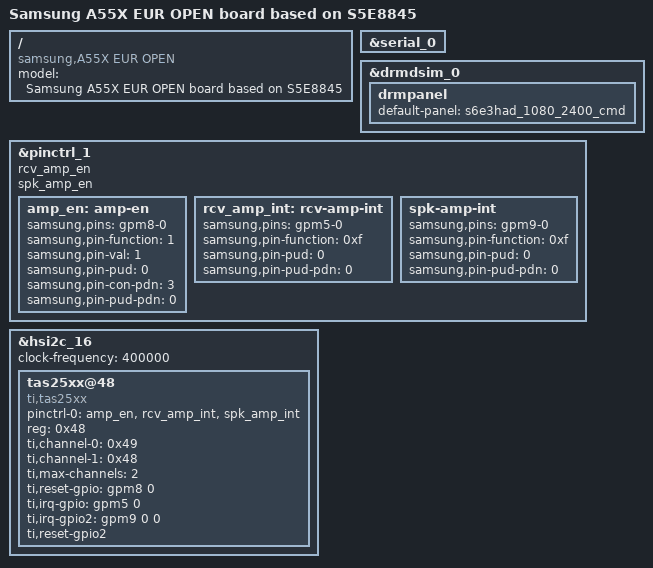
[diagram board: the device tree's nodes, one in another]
/*
 * SAMSUNG S5E8845 board device tree source
 *
 * Copyright (c) 2023 Samsung Electronics Co., Ltd.
 *		http://www.samsung.com
 *
 * This program is free software; you can redistribute it and/or modify
 * it under the terms of the GNU General Public License version 2 as
 * published by the Free Software Foundation.
 */

#include "s5e8845-a55x_common.dtsi"
//#include "panel/samsung-emulation-video-panel.dtsi"
//#include "../../exynos/board/panel/samsung-s6e3had-1080-2400-command-panel.dtsi"
#include "camera/s5e8845-a55x-camera_01.dtsi"

/ {
	compatible = "samsung,A55X EUR OPEN", "samsung,S5E8845";

	fragment@model {
		target-path = "/";
		__overlay__ {
			#address-cells = <2>;
			#size-cells = <1>;

			model = "Samsung A55X EUR OPEN board based on S5E8845";
		}; /* end of __overlay__ */
	}; /* end of fragment */
}; /* end of root */

&serial_0 {
	status = "okay";
};

&drmdsim_0 {
        drmpanel {
                default-panel = "s6e3had_1080_2400_cmd";
        };
};

&pinctrl_1 {
	rcv_amp_en;
	spk_amp_en;
	amp_en: amp-en {
		samsung,pins ="gpm8-0";
		samsung,pin-function = <1>;
		samsung,pin-val = <1>;
		samsung,pin-pud = <0>;
		samsung,pin-con-pdn = <3>;
		samsung,pin-pud-pdn = <0>;
	};
	rcv_amp_int: rcv-amp-int {
		samsung,pins ="gpm5-0";
		samsung,pin-function = <0xf>;
		samsung,pin-pud = <0>;
		samsung,pin-pud-pdn = <0>;
	};
	spk-amp-int {
		samsung,pins ="gpm9-0";
		samsung,pin-function = <0xf>;
		samsung,pin-pud = <0>;
		samsung,pin-pud-pdn = <0>;
	};
};

&hsi2c_16 {
	#address-cells = <1>;
	#size-cells = <0>;
	status = "okay";
	clock-frequency = <400000>;

	tas25xx@48 {
		pinctrl-names = "default";
		pinctrl-0 = <&amp_en &rcv_amp_int &spk_amp_int>;
		#sound-dai-cells = <1>;
		compatible = "ti,tas25xx";
		reg = <0x48>;
		ti,channel-0 = <0x49>;
		ti,channel-1 = <0x48>;
		ti,max-channels = <2>;
		ti,reset-gpio = <&gpm8 0 0>; // shared
		ti,irq-gpio = <&gpm5 0 0>;
		ti,irq-gpio2 = <&gpm9 0 0>;
		ti,reset-gpio2;
		status = "okay";
	};

};
